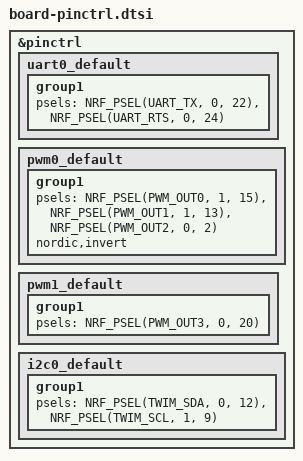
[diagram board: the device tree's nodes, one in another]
&pinctrl {
  uart0_default: uart0_default {
    group1 {
      psels = <NRF_PSEL(UART_TX, 0, 22)>,
              <NRF_PSEL(UART_RTS, 0, 24)>;
    };
  };

  pwm0_default: pwm0_default {
    group1 {
      psels = <NRF_PSEL(PWM_OUT0, 1, 15)>,
              <NRF_PSEL(PWM_OUT1, 1, 13)>,
              <NRF_PSEL(PWM_OUT2, 0, 2)>;
      nordic,invert;
    };
  };

  pwm1_default: pwm1_default {
    group1 {
      psels = <NRF_PSEL(PWM_OUT3, 0, 20)>;
    };
  };

  i2c0_default: i2c0_default {
    group1 {
      psels = <NRF_PSEL(TWIM_SDA, 0, 12)>,
              <NRF_PSEL(TWIM_SCL, 1, 9)>;
    };
  };
};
